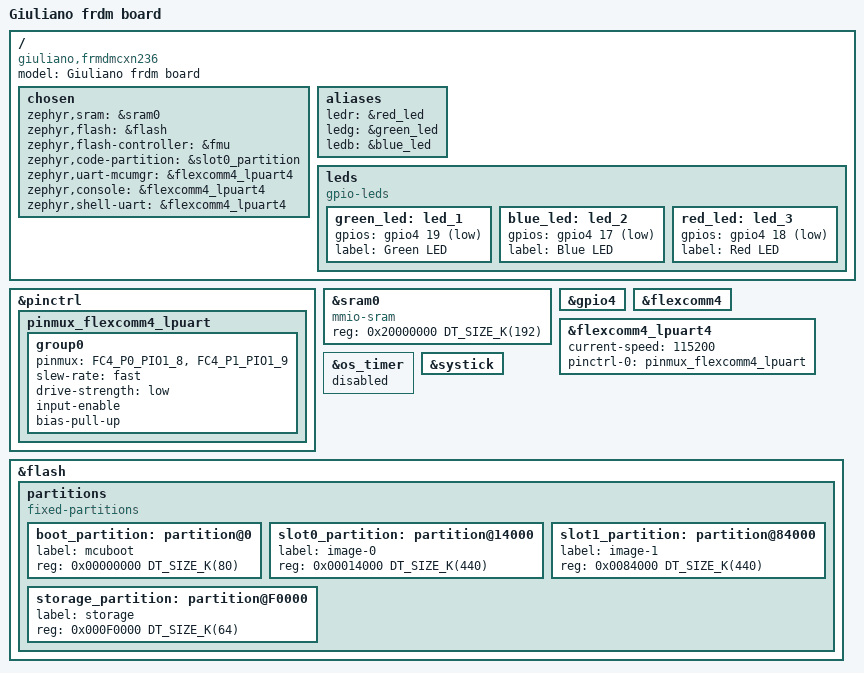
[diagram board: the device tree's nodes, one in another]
/*
 * Copyright 2024-2025 NXP
 *
 * SPDX-License-Identifier: Apache-2.0
 */

/dts-v1/;

#include <nxp/nxp_mcxn23x.dtsi>
#include <zephyr/dt-bindings/i2c/i2c.h>
#include <zephyr/dt-bindings/gpio/arduino-header-r3.h>
#include <zephyr/dt-bindings/input/input-event-codes.h>
#include <zephyr/dt-bindings/gpio/dvp-20pin-connector.h>
#include <nxp/mcx/MCXN236VDF-pinctrl.h>

&pinctrl {
	pinmux_flexcomm4_lpuart: pinmux_flexcomm4_lpuart {
		group0 {
			pinmux = <FC4_P0_PIO1_8>,
				 <FC4_P1_PIO1_9>;
			slew-rate = "fast";
			drive-strength = "low";
			input-enable;
			bias-pull-up;
		};
	};
};


/ {
	model = "Giuliano frdm board";
	compatible = "giuliano,frmdmcxn236";

	chosen {
		zephyr,sram = &sram0;
		zephyr,flash = &flash;
		zephyr,flash-controller = &fmu;
		zephyr,code-partition = &slot0_partition;
		zephyr,uart-mcumgr = &flexcomm4_lpuart4;
		zephyr,console = &flexcomm4_lpuart4;
		zephyr,shell-uart = &flexcomm4_lpuart4;
	};

	aliases {
		ledr = &red_led;
		ledg = &green_led;
		ledb = &blue_led;
	};

	leds {
		compatible = "gpio-leds";

		green_led: led_1 {
			gpios = <&gpio4 19 GPIO_ACTIVE_LOW>;
			label = "Green LED";
		};

		blue_led: led_2 {
			gpios = <&gpio4 17 GPIO_ACTIVE_LOW>;
			label = "Blue LED";
		};

		red_led: led_3 {
			gpios = <&gpio4 18 GPIO_ACTIVE_LOW>;
			label = "Red LED";
		};
	};
};

&sram0 {
	compatible = "mmio-sram";
	reg = <0x20000000 DT_SIZE_K(192)>;
};

&gpio4 {
	status = "okay";
};

&green_led {
	status = "okay";
};

&red_led {
	status = "okay";
};

&flexcomm4 {
	status = "okay";
};

&flexcomm4_lpuart4 {
	status = "okay";
};

&flexcomm4_lpuart4 {
	current-speed = <115200>;
	pinctrl-0 = <&pinmux_flexcomm4_lpuart>;
	pinctrl-names = "default";
};


/*
 * MCXN236 board uses OS timer as the kernel timer
 * In case we need to switch to SYSTICK timer, then
 * replace &os_timer with &systick
 */
&os_timer {
	status = "disabled";
};

&systick {
	status = "okay";
};

&flash {
	partitions {
		compatible = "fixed-partitions";
		#address-cells = <1>;
		#size-cells = <1>;

		/*
		 * Partition sizes must be aligned
		 * to the flash memory sector size of 8KB.
		 */
		boot_partition: partition@0 {
			label = "mcuboot";
			reg = <0x00000000 DT_SIZE_K(80)>;
		};

		/* For the MCUBoot "upgrade only" method,
		 * the slot sizes must be equal.
		 */
		slot0_partition: partition@14000 {
			label = "image-0";
			reg = <0x00014000 DT_SIZE_K(440)>;
		};

		slot1_partition: partition@84000 {
			label = "image-1";
			reg = <0x0084000 DT_SIZE_K(440)>;
		};

		storage_partition: partition@F0000 {
			label = "storage";
			reg = <0x000F0000 DT_SIZE_K(64)>;
		};
	};
};
